AUTOSAR XML (schema 4-3-1)
standard types defined: Double, float64
package /Timing
  swc timing autosar_swc_timing: behavior=test_IB12
    timing-requirements:
      execution order constraint EOC
        ordered-elements:
          eoc executable entity ref Runnable_1s: executable=Runnable_1s
          eoc executable entity ref Runnable_2S: executable=Runnable_2S, successor=Runnable_1s
package /Interfaces
  sender receiver interface In2_2S
    data In2_2S: category=VALUE, sw-calibration-access=READ-ONLY, type=Double
  sender receiver interface Out1
    data Out1: category=VALUE, sw-calibration-access=READ-ONLY, type=Double
  sender receiver interface Out2
    data Out2: category=VALUE, sw-calibration-access=READ-ONLY, type=Double
package /Interfaces/test
  sender receiver interface In1_1s
    data In1_1s: category=VALUE, sw-calibration-access=READ-ONLY, type=Double
    data New: category=VALUE, sw-calibration-access=READ-ONLY, type=Double
package /DataTypes/SwAddrMethods
  sw addr method CODE: section-type=CODE
  sw addr method CONST: section-type=CONST
  sw addr method VAR: section-type=VAR
package /Components
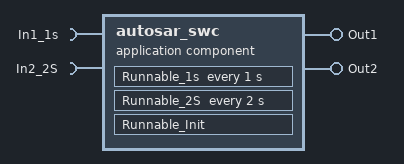
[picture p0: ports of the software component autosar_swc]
  application sw component type autosar_swc
    provide port Out1: nonqueued-sender-com-spec{data-element=Out1, init-value=0}, provided-interface=Out1
    provide port Out2: nonqueued-sender-com-spec{data-element=Out2, init-value=0}, provided-interface=Out2
    require port In1_1s: nonqueued-receiver-com-spec{data-element=In1_1s, init-value=0}, required-interface=In1_1s
    require port In2_2S: nonqueued-receiver-com-spec{data-element=In2_2S, init-value=0}, required-interface=In2_2S
    behavior test_IB12: handle-termination-and-restart=NO-SUPPORT
      timing event Event_test_Step: start-on-event=Runnable_1s, period=1
      timing event Event: start-on-event=Runnable_2S, period=2
      implicit-inter-runnable-variables:
        data IRV1: category=VALUE, sw-calibration-access=READ-ONLY, type=Double, init-value=0
      runnable Runnable_Init: symbol=test_Init
      runnable Runnable_1s
        data-read-access:
          access IN_In1_1s_In1_1s: accessed-variable=In1_1s.In1_1s
        data-write-access:
          access OUT_Out1_Out1: accessed-variable=Out1.Out1
          access OUT_Out2_Out2: accessed-variable=Out2.Out2
        read-local-variables:
          access RV_IRV1: accessed-variable=IRV1
      runnable Runnable_2S: symbol=Runnable_2s
        data-read-access:
          access IN_In2_2S_In2_2S: accessed-variable=In2_2S.In2_2S
        written-local-variables:
          access WV_IRV1: accessed-variable=IRV1
package /Components/SwcImplementations
  swc implementation test_Impl: programming-language=C, sw-version=1.27.1, used-code-generator=ARXML Coder Generator 1.0 (Wumbuk) 04-OCT-2023, vendor-id=0, behavior=test_IB12
    code-descriptors:
      code Code
        artifact-descriptors:
          short-label=autosar_swc_c, category=SWSRC
          short-label=rtwtypes_h, category=SWHDR
          short-label=autosar_swc_h, category=SWHDR
    resource consumption RsrcCons_autosar_swc
